AUTOSAR XML (schema 4-0-3)
package /ComponentTypes
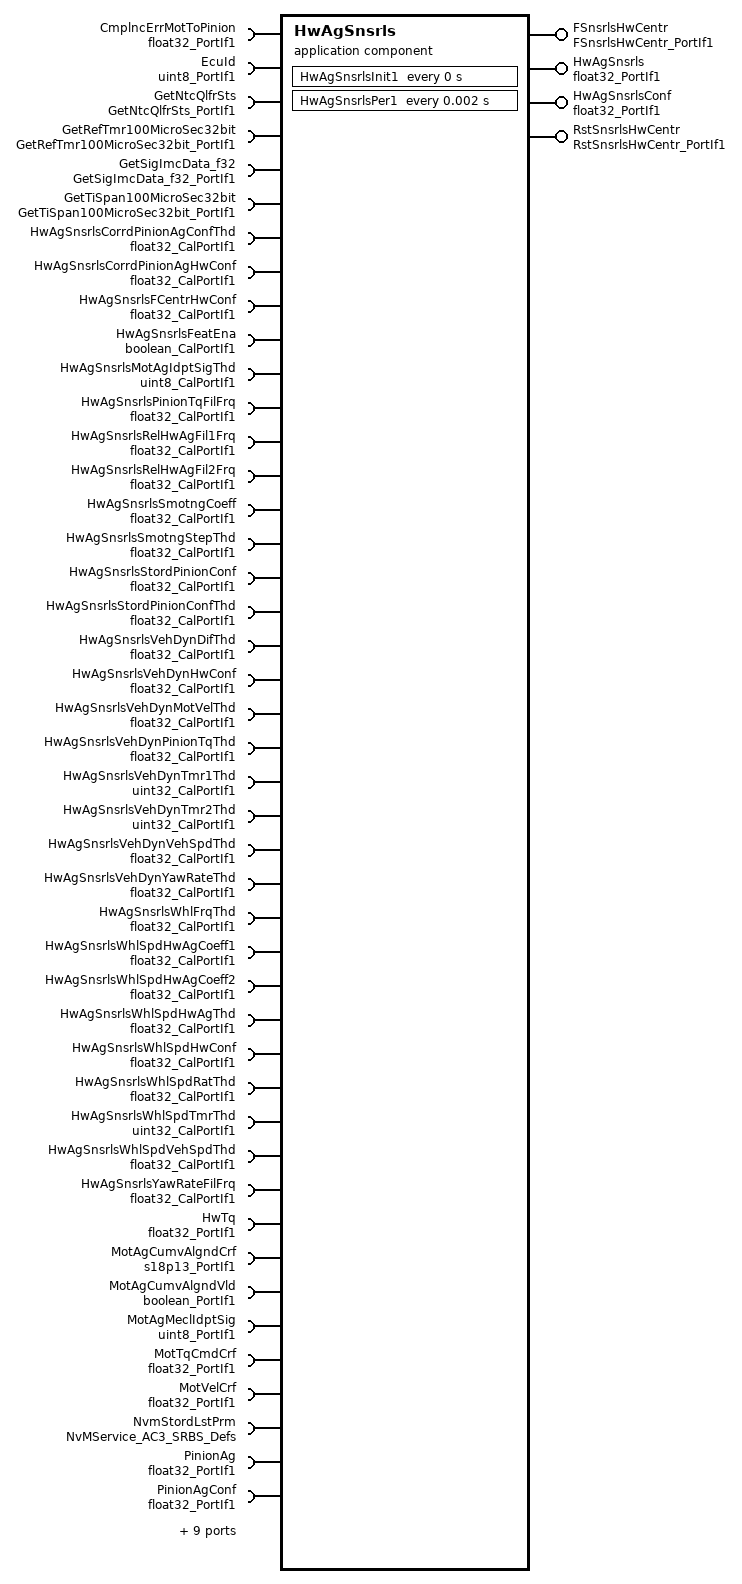
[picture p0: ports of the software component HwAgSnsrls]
  application sw component type HwAgSnsrls
    4 x provide port:
      FSnsrlsHwCentr: server-com-spec{operation=Oper, queue-length=1}, provided-interface=FSnsrlsHwCentr_PortIf1
      HwAgSnsrls: nonqueued-sender-com-spec{data-element=Val, init-value=0}, provided-interface=float32_PortIf1
      HwAgSnsrlsConf: nonqueued-sender-com-spec{data-element=Val, init-value=0}, provided-interface=float32_PortIf1
      RstSnsrlsHwCentr: server-com-spec{operation=Oper, queue-length=1}, provided-interface=RstSnsrlsHwCentr_PortIf1
    53 x require port:
      CmplncErrMotToPinion: nonqueued-receiver-com-spec{data-element=Val, filter=data-filter-type=ALWAYS, init-value=0}, required-interface=float32_PortIf1
      EcuId: nonqueued-receiver-com-spec{data-element=Val, filter=data-filter-type=ALWAYS, init-value=0}, required-interface=uint8_PortIf1
      GetNtcQlfrSts: client-com-spec=Oper, required-interface=GetNtcQlfrSts_PortIf1
      GetRefTmr100MicroSec32bit: client-com-spec=Oper, required-interface=GetRefTmr100MicroSec32bit_PortIf1
      GetSigImcData_f32: client-com-spec=Oper, required-interface=GetSigImcData_f32_PortIf1
      GetTiSpan100MicroSec32bit: client-com-spec=Oper, required-interface=GetTiSpan100MicroSec32bit_PortIf1
      HwAgSnsrlsCorrdPinionAgConfThd: parameter-require-com-spec{init-value=0.9, parameter=Val}, required-interface=float32_CalPortIf1
      HwAgSnsrlsCorrdPinionAgHwConf: parameter-require-com-spec{init-value=1, parameter=Val}, required-interface=float32_CalPortIf1
      HwAgSnsrlsFCentrHwConf: parameter-require-com-spec{init-value=1, parameter=Val}, required-interface=float32_CalPortIf1
      HwAgSnsrlsFeatEna: parameter-require-com-spec{init-value=0, parameter=Logl}, required-interface=boolean_CalPortIf1
      HwAgSnsrlsMotAgIdptSigThd: parameter-require-com-spec{init-value=1, parameter=Val}, required-interface=uint8_CalPortIf1
      HwAgSnsrlsPinionTqFilFrq: parameter-require-com-spec{init-value=0.035, parameter=Val}, required-interface=float32_CalPortIf1
      HwAgSnsrlsRelHwAgFil1Frq: parameter-require-com-spec{init-value=0.025, parameter=Val}, required-interface=float32_CalPortIf1
      HwAgSnsrlsRelHwAgFil2Frq: parameter-require-com-spec{init-value=0.025, parameter=Val}, required-interface=float32_CalPortIf1
      HwAgSnsrlsSmotngCoeff: parameter-require-com-spec{init-value=0.2, parameter=Val}, required-interface=float32_CalPortIf1
      HwAgSnsrlsSmotngStepThd: parameter-require-com-spec{init-value=5, parameter=Val}, required-interface=float32_CalPortIf1
      HwAgSnsrlsStordPinionConf: parameter-require-com-spec{init-value=0.1, parameter=Val}, required-interface=float32_CalPortIf1
      HwAgSnsrlsStordPinionConfThd: parameter-require-com-spec{init-value=0.1, parameter=Val}, required-interface=float32_CalPortIf1
      HwAgSnsrlsVehDynDifThd: parameter-require-com-spec{init-value=5, parameter=Val}, required-interface=float32_CalPortIf1
      HwAgSnsrlsVehDynHwConf: parameter-require-com-spec{init-value=0, parameter=Val}, required-interface=float32_CalPortIf1
      HwAgSnsrlsVehDynMotVelThd: parameter-require-com-spec{init-value=20, parameter=Val}, required-interface=float32_CalPortIf1
      HwAgSnsrlsVehDynPinionTqThd: parameter-require-com-spec{init-value=3, parameter=Val}, required-interface=float32_CalPortIf1
      HwAgSnsrlsVehDynTmr1Thd: parameter-require-com-spec{init-value=1500, parameter=Val}, required-interface=uint32_CalPortIf1
      HwAgSnsrlsVehDynTmr2Thd: parameter-require-com-spec{init-value=2000, parameter=Val}, required-interface=uint32_CalPortIf1
      HwAgSnsrlsVehDynVehSpdThd: parameter-require-com-spec{init-value=65, parameter=Val}, required-interface=float32_CalPortIf1
      HwAgSnsrlsVehDynYawRateThd: parameter-require-com-spec{init-value=1, parameter=Val}, required-interface=float32_CalPortIf1
      HwAgSnsrlsWhlFrqThd: parameter-require-com-spec{init-value=0.2, parameter=Val}, required-interface=float32_CalPortIf1
      HwAgSnsrlsWhlSpdHwAgCoeff1: parameter-require-com-spec{init-value=4000, parameter=Val}, required-interface=float32_CalPortIf1
      HwAgSnsrlsWhlSpdHwAgCoeff2: parameter-require-com-spec{init-value=0, parameter=Val}, required-interface=float32_CalPortIf1
      HwAgSnsrlsWhlSpdHwAgThd: parameter-require-com-spec{init-value=600, parameter=Val}, required-interface=float32_CalPortIf1
      HwAgSnsrlsWhlSpdHwConf: parameter-require-com-spec{init-value=0.2, parameter=Val}, required-interface=float32_CalPortIf1
      HwAgSnsrlsWhlSpdRatThd: parameter-require-com-spec{init-value=0.00001, parameter=Val}, required-interface=float32_CalPortIf1
      HwAgSnsrlsWhlSpdTmrThd: parameter-require-com-spec{init-value=500, parameter=Val}, required-interface=uint32_CalPortIf1
      HwAgSnsrlsWhlSpdVehSpdThd: parameter-require-com-spec{init-value=0.1, parameter=Val}, required-interface=float32_CalPortIf1
      HwAgSnsrlsYawRateFilFrq: parameter-require-com-spec{init-value=3, parameter=Val}, required-interface=float32_CalPortIf1
      HwTq: nonqueued-receiver-com-spec{data-element=Val, filter=data-filter-type=ALWAYS, init-value=0}, required-interface=float32_PortIf1
      MotAgCumvAlgndCrf: nonqueued-receiver-com-spec{data-element=Val, filter=data-filter-type=ALWAYS, init-value=0}, required-interface=s18p13_PortIf1
      MotAgCumvAlgndVld: nonqueued-receiver-com-spec{data-element=Logl, filter=data-filter-type=ALWAYS, init-value=0}, required-interface=boolean_PortIf1
      MotAgMeclIdptSig: nonqueued-receiver-com-spec{data-element=Val, filter=data-filter-type=ALWAYS, init-value=3}, required-interface=uint8_PortIf1
      MotTqCmdCrf: nonqueued-receiver-com-spec{data-element=Val, filter=data-filter-type=ALWAYS, init-value=0}, required-interface=float32_PortIf1
      MotVelCrf: nonqueued-receiver-com-spec{data-element=Val, filter=data-filter-type=ALWAYS, init-value=0}, required-interface=float32_PortIf1
      NvmStordLstPrm: required-com-specs=[EraseBlock, GetErrorStatus, InvalidateNvBlock, ReadBlock, RestoreBlockDefaults, SetRamBlockStatus, WriteBlock], required-interface=NvMService_AC3_SRBS_Defs
      PinionAg: nonqueued-receiver-com-spec{data-element=Val, filter=data-filter-type=ALWAYS, init-value=0}, required-interface=float32_PortIf1
      PinionAgConf: nonqueued-receiver-com-spec{data-element=Val, filter=data-filter-type=ALWAYS, init-value=0}, required-interface=float32_PortIf1
      SysGlbPrmSysKineRat: parameter-require-com-spec{init-value=22, parameter=Val}, required-interface=float32_CalPortIf1
      SysGlbPrmSysTqRat: parameter-require-com-spec{init-value=20, parameter=Val}, required-interface=float32_CalPortIf1
      VehSpd: nonqueued-receiver-com-spec{data-element=Val, filter=data-filter-type=ALWAYS, init-value=0}, required-interface=float32_PortIf1
      VehSpdVld: nonqueued-receiver-com-spec{data-element=Logl, filter=data-filter-type=ALWAYS, init-value=0}, required-interface=boolean_PortIf1
      VehYawRate: nonqueued-receiver-com-spec{data-element=Val, filter=data-filter-type=ALWAYS, init-value=0}, required-interface=float32_PortIf1
      VehYawRateVld: nonqueued-receiver-com-spec{data-element=Logl, filter=data-filter-type=ALWAYS, init-value=0}, required-interface=boolean_PortIf1
      WhlFrqVld: nonqueued-receiver-com-spec{data-element=Logl, filter=data-filter-type=ALWAYS, init-value=0}, required-interface=boolean_PortIf1
      WhlLeFrq: nonqueued-receiver-com-spec{data-element=Val, filter=data-filter-type=ALWAYS, init-value=0.01}, required-interface=float32_PortIf1
      WhlRiFrq: nonqueued-receiver-com-spec{data-element=Val, filter=data-filter-type=ALWAYS, init-value=0.01}, required-interface=float32_PortIf1
    behavior HwAgSnsrls_InternalBehavior
      ar-typed-per-instance-memorys:
        31 x data, all with sw-calibration-access=READ-ONLY:
          CorrdPinionAgHwAgOffs: type=float32
          CorrdPinionAgHwConf: type=float32
          dHwAgSnsrlsStordHwAg: type=float32
          dHwAgSnsrlsStordHwConf: type=float32
          dHwAgSnsrlsVehDynHwConf: type=float32
          dHwAgSnsrlsWhlSpdHwConf: type=float32
          FCentrHwAgEna: type=boolean
          FCentrHwAgOffs: type=float32
          FCentrHwConf: type=float32
          MotAgOffs: type=float32
          MotAgOffsEna: type=boolean
          PinionTqFil: type=FilLpRec1
          PrevFildRelHwAg1: type=float32
          PrevHwAgOffs: type=float32
          PrevMaxHwConf: type=float32
          PrevSmotngHwAg: type=float32
          PrevSmotngSt: type=boolean
          PrevVehDynFil1Ena: type=boolean
          PrevVehDynFil2Ena: type=boolean
          RelHwAgFil1: type=FilLpRec1
          RelHwAgFil2: type=FilLpRec1
          SelnCaseSt: type=SelnCaseSt1
          StordLstPrm: type=StordLstPrmRec1
          VehDynHwAgOffs: type=float32
          VehDynRefTmr1: type=uint32
          VehDynRefTmr2: type=uint32
          WhlSpdHwAgLrndEna: type=boolean
          WhlSpdHwAgOffs: type=float32
          WhlSpdHwConf: type=float32
          WhlSpdRefTmr: type=uint32
          YawRateFil: type=FilLpRec1
      operation invoked event OIT_FSnsrlsHwCentr_Oper_FSnsrlsHwCentr_Oper: start-on-event=FSnsrlsHwCentr_Oper, operation=FSnsrlsHwCentr.Oper
      timing event HwAgSnsrls_InitEvent: start-on-event=HwAgSnsrlsInit1, period=0
      timing event TMT_HwAgSnsrlsPer1: start-on-event=HwAgSnsrlsPer1, period=0.002
      operation invoked event OIT_RstSnsrlsHwCentr_Oper_RstSnsrlsHwCentr_Oper: start-on-event=RstSnsrlsHwCentr_Oper, operation=RstSnsrlsHwCentr.Oper
      explicit-inter-runnable-variables:
        data StordHwAg: type=float32, init-value=0
        data StordHwConf: type=float32, init-value=0
      port-api-options:
        enable-take-address=false, indirect-api=false, port=CmplncErrMotToPinion
        enable-take-address=false, indirect-api=false, port=EcuId
        enable-take-address=false, indirect-api=false, port=FSnsrlsHwCentr
        enable-take-address=false, indirect-api=false, port=GetNtcQlfrSts
        enable-take-address=false, indirect-api=false, port=GetRefTmr100MicroSec32bit
        enable-take-address=false, indirect-api=false, port=GetSigImcData_f32
        enable-take-address=false, indirect-api=false, port=GetTiSpan100MicroSec32bit
        enable-take-address=false, indirect-api=false, port=HwAgSnsrls
        enable-take-address=false, indirect-api=false, port=HwAgSnsrlsConf
        enable-take-address=false, indirect-api=false, port=HwAgSnsrlsCorrdPinionAgConfThd
        enable-take-address=false, indirect-api=false, port=HwAgSnsrlsCorrdPinionAgHwConf
        enable-take-address=false, indirect-api=false, port=HwAgSnsrlsFCentrHwConf
        enable-take-address=false, indirect-api=false, port=HwAgSnsrlsFeatEna
        enable-take-address=false, indirect-api=false, port=HwAgSnsrlsMotAgIdptSigThd
        enable-take-address=false, indirect-api=false, port=HwAgSnsrlsPinionTqFilFrq
        enable-take-address=false, indirect-api=false, port=HwAgSnsrlsRelHwAgFil1Frq
        enable-take-address=false, indirect-api=false, port=HwAgSnsrlsRelHwAgFil2Frq
        enable-take-address=false, indirect-api=false, port=HwAgSnsrlsSmotngCoeff
        enable-take-address=false, indirect-api=false, port=HwAgSnsrlsSmotngStepThd
        enable-take-address=false, indirect-api=false, port=HwAgSnsrlsStordPinionConf
        enable-take-address=false, indirect-api=false, port=HwAgSnsrlsStordPinionConfThd
        enable-take-address=false, indirect-api=false, port=HwAgSnsrlsVehDynDifThd
        enable-take-address=false, indirect-api=false, port=HwAgSnsrlsVehDynHwConf
        enable-take-address=false, indirect-api=false, port=HwAgSnsrlsVehDynMotVelThd
        enable-take-address=false, indirect-api=false, port=HwAgSnsrlsVehDynPinionTqThd
        enable-take-address=false, indirect-api=false, port=HwAgSnsrlsVehDynTmr1Thd
        enable-take-address=false, indirect-api=false, port=HwAgSnsrlsVehDynTmr2Thd
        enable-take-address=false, indirect-api=false, port=HwAgSnsrlsVehDynVehSpdThd
        enable-take-address=false, indirect-api=false, port=HwAgSnsrlsVehDynYawRateThd
        enable-take-address=false, indirect-api=false, port=HwAgSnsrlsWhlFrqThd
        enable-take-address=false, indirect-api=false, port=HwAgSnsrlsWhlSpdHwAgCoeff1
        enable-take-address=false, indirect-api=false, port=HwAgSnsrlsWhlSpdHwAgCoeff2
        enable-take-address=false, indirect-api=false, port=HwAgSnsrlsWhlSpdHwAgThd
        enable-take-address=false, indirect-api=false, port=HwAgSnsrlsWhlSpdHwConf
        enable-take-address=false, indirect-api=false, port=HwAgSnsrlsWhlSpdRatThd
        enable-take-address=false, indirect-api=false, port=HwAgSnsrlsWhlSpdTmrThd
        enable-take-address=false, indirect-api=false, port=HwAgSnsrlsWhlSpdVehSpdThd
        enable-take-address=false, indirect-api=false, port=HwAgSnsrlsYawRateFilFrq
        enable-take-address=false, indirect-api=false, port=HwTq
        enable-take-address=false, indirect-api=false, port=MotAgCumvAlgndCrf
        enable-take-address=false, indirect-api=false, port=MotAgCumvAlgndVld
        enable-take-address=false, indirect-api=false, port=MotAgMeclIdptSig
        enable-take-address=false, indirect-api=false, port=MotTqCmdCrf
        enable-take-address=false, indirect-api=false, port=MotVelCrf
        enable-take-address=false, indirect-api=false, port=NvmStordLstPrm
        enable-take-address=false, indirect-api=false, port=PinionAg
        enable-take-address=false, indirect-api=false, port=PinionAgConf
        enable-take-address=false, indirect-api=false, port=RstSnsrlsHwCentr
        enable-take-address=false, indirect-api=false, port=SysGlbPrmSysKineRat
        enable-take-address=false, indirect-api=false, port=SysGlbPrmSysTqRat
        enable-take-address=false, indirect-api=false, port=VehSpd
        enable-take-address=false, indirect-api=false, port=VehSpdVld
        enable-take-address=false, indirect-api=false, port=VehYawRate
        enable-take-address=false, indirect-api=false, port=VehYawRateVld
        enable-take-address=false, indirect-api=false, port=WhlFrqVld
        enable-take-address=false, indirect-api=false, port=WhlLeFrq
        enable-take-address=false, indirect-api=false, port=WhlRiFrq
      4 x runnable:
        FSnsrlsHwCentr_Oper
        HwAgSnsrlsInit1
          sync call AC_NvmStordLstPrm_SetRamBlockStatus: operation=NvmStordLstPrm.SetRamBlockStatus, timeout=0
          sync call SC_GetNtcQlfrSts_Oper: operation=GetNtcQlfrSts.Oper, timeout=0
          sync call SC_GetRefTmr100MicroSec32bit_Oper: operation=GetRefTmr100MicroSec32bit.Oper, timeout=0
          written-local-variables:
            access WRITE_StordHwAg: accessed-variable=StordHwAg
            access WRITE_StordHwConf: accessed-variable=StordHwConf
        HwAgSnsrlsPer1
          data-receive-point-by-arguments:
            17 x access:
              REC_CmplncErrMotToPinion_Val: accessed-variable=CmplncErrMotToPinion.Val
              REC_EcuId_Val: accessed-variable=EcuId.Val
              REC_HwTq_Val: accessed-variable=HwTq.Val
              REC_MotAgCumvAlgndCrf_Val: accessed-variable=MotAgCumvAlgndCrf.Val
              REC_MotAgCumvAlgndVld_Logl: accessed-variable=MotAgCumvAlgndVld.Logl
              REC_MotAgMeclIdptSig_Val: accessed-variable=MotAgMeclIdptSig.Val
              REC_MotTqCmdCrf_Val: accessed-variable=MotTqCmdCrf.Val
              REC_MotVelCrf_Val: accessed-variable=MotVelCrf.Val
              REC_PinionAg_Val: accessed-variable=PinionAg.Val
              REC_PinionAgConf_Val: accessed-variable=PinionAgConf.Val
              REC_VehSpd_Val: accessed-variable=VehSpd.Val
              REC_VehSpdVld_Logl: accessed-variable=VehSpdVld.Logl
              REC_VehYawRate_Val: accessed-variable=VehYawRate.Val
              REC_VehYawRateVld_Logl: accessed-variable=VehYawRateVld.Logl
              REC_WhlFrqVld_Logl: accessed-variable=WhlFrqVld.Logl
              REC_WhlLeFrq_Val: accessed-variable=WhlLeFrq.Val
              REC_WhlRiFrq_Val: accessed-variable=WhlRiFrq.Val
          data-send-points:
            access SEND_HwAgSnsrls_Val: accessed-variable=HwAgSnsrls.Val
            access SEND_HwAgSnsrlsConf_Val: accessed-variable=HwAgSnsrlsConf.Val
          read-local-variables:
            access READ_StordHwAg: accessed-variable=StordHwAg
            access READ_StordHwConf: accessed-variable=StordHwConf
          sync call SC_GetRefTmr100MicroSec32bit_Oper: operation=GetRefTmr100MicroSec32bit.Oper, timeout=0
          sync call SC_GetSigImcData_Oper: operation=GetSigImcData_f32.Oper, timeout=0
          sync call SC_GetTiSpan100MicroSec32bit_Oper: operation=GetTiSpan100MicroSec32bit.Oper, timeout=0
        RstSnsrlsHwCentr_Oper
      swc service dependency NvmStordLstPrm: assigned-ports=role-based-port-assignment={port-prototype=NvmStordLstPrm, role=NvMService_AC3_SRBS_Defs}
        assigned-datas:
          role=ramBlock, used-data-element=StordLstPrm
          role=defaultValue, used-parameter-element=StordLstPrmDft
        service-needs:
          nv block needs NvmStordLstPrm: n-data-sets=0, readonly=false, reliability=ERROR-DETECTION, resistant-to-changed-sw=true, write-only-once=false, writing-frequency=0, writing-priority=LOW
      shared-parameters:
        parameter data prototype StordLstPrmDft: sw-calibration-access=READ-WRITE, type=StordLstPrmRec1, init-value=fields=[ElementConstant:0, ElementConstant:0]
  swc implementation HwAgSnsrls_Implementation: behavior=HwAgSnsrls_InternalBehavior
    code-descriptors:
      code Default: artifact-descriptors=autosar-engineering-object={short-label=Default, category=SWSRC}
